# MIMXRT1064 register map
Vendor: nxp.com; File version: 1.0
CPU: CM7 r0p1, little endian, MPU, FPU, VTOR, 4 interrupt priority bits
Registers are 32-bit, read-write, reset 0x0 unless marked. A register's access mark holds for its fields unless they carry their own. Offsets are from the block's base; [hi:lo] are bit positions; {n}, {i} and the like mark numbered series; 'fields as' and 'values as' point back to an identical list.

## GPIO1 — GPIO
Base 0x401B8000
Same registers: GPIO5 0x400C0000, GPIO2 0x401BC000, GPIO3 0x401C0000, GPIO4 0x401C4000, GPIO10 0x401C8000, GPIO6 0x42000000, GPIO7 0x42004000, GPIO8 0x42008000, GPIO9 0x4200C000
0x00 DR — GPIO data register
  [31:0] DR — DR data bits
0x04 GDIR — GPIO direction register
  [31:0] GDIR — GPIO direction bits
0x08 PSR ro — GPIO pad status register
  [31:0] PSR — GPIO pad status bits
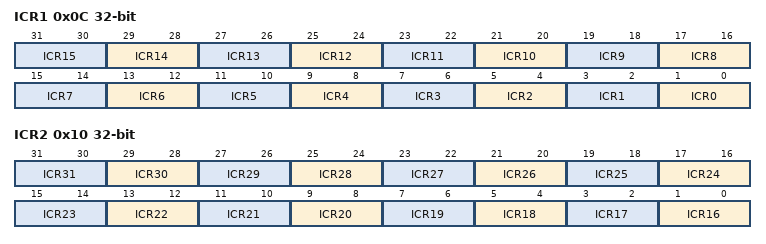
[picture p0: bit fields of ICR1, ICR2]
0x0C ICR1 — GPIO interrupt configuration register1
  [2n+1:2n] ICR{n} (n=0..15) — Interrupt configuration field for GPIO interrupt {n}
    0=LOW_LEVEL (Interrupt {n} is low-level sensitive.); 1=HIGH_LEVEL (Interrupt {n} is high-level sensitive.); 2=RISING_EDGE (Interrupt {n} is rising-edge sensitive.); 3=FALLING_EDGE (Interrupt {n} is falling-edge sensitive.)
0x10 ICR2 — GPIO interrupt configuration register2
  [2n-31:2n-32] ICR{n} (n=16..31) — Interrupt configuration field for GPIO interrupt {n}
    values as ICR1.ICR0
0x14 IMR — GPIO interrupt mask register
  [31:0] IMR — Interrupt Mask bits
0x18 ISR write-1-clears — GPIO interrupt status register
  [31:0] ISR write-1-clears — Interrupt status bits
0x1C EDGE_SEL — GPIO edge select register
  [31:0] GPIO_EDGE_SEL — Edge select
0x84 DR_SET wo — GPIO data register SET
  [31:0] DR_SET — Set
0x88 DR_CLEAR wo — GPIO data register CLEAR
  [31:0] DR_CLEAR — Clear
0x8C DR_TOGGLE wo — GPIO data register TOGGLE
  [31:0] DR_TOGGLE — Toggle

## KPP — KPP Registers
Base 0x401FC000; register names take the prefix KPP_
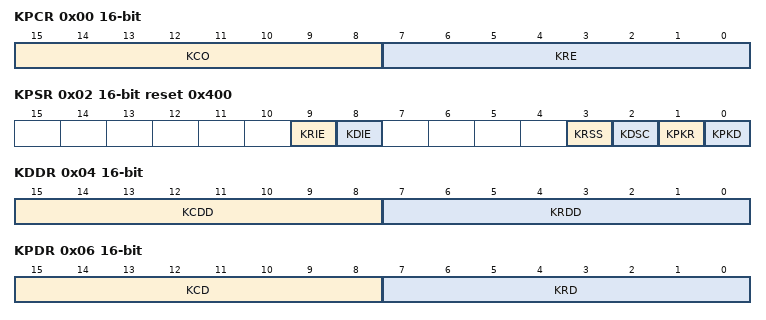
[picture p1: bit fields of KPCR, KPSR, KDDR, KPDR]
0x00 KPCR 16-bit — Keypad Control Register
  [15:8] KCO — Keypad Column Strobe Open-Drain Enable
    0=TOTEM_POLE (Column strobe output is totem pole drive.); 1=OPEN_DRAIN (Column strobe output is open drain.)
  [7:0] KRE — Keypad Row Enable
    0=Row is not included in the keypad key press detect; 1=Row is included in the keypad key press detect
0x02 KPSR 16-bit reset 0x400 — Keypad Status Register
  [9] KRIE — Keypad Release Interrupt Enable
    0=No interrupt request is generated when KPKR is set; 1=An interrupt request is generated when KPKR is set
  [8] KDIE — Keypad Key Depress Interrupt Enable
    0=No interrupt request is generated when KPKD is set; 1=An interrupt request is generated when KPKD is set
  [3] KRSS — Key Release Synchronizer Set
    0=No effect; 1=Set bits which sets keypad release synchronizer chain
  [2] KDSC — Key Depress Synchronizer Clear
    0=No effect; 1=Set bits that clear the keypad depress synchronizer chain
  [1] KPKR write-1-clears — Keypad Key Release
    0=No key release detected; 1=All keys have been released
  [0] KPKD write-1-clears — Keypad Key Depress
    0=No key presses detected; 1=A key has been depressed
0x04 KDDR 16-bit — Keypad Data Direction Register
  [15:8] KCDD — Keypad Column Data Direction Register
    0=INPUT (COLn pin is configured as an input.); 1=OUTPUT (COLn pin is configured as an output.)
  [7:0] KRDD — Keypad Row Data Direction
    0=INPUT (ROWn pin configured as an input.); 1=OUTPUT (ROWn pin configured as an output.)
0x06 KPDR 16-bit — Keypad Data Register
  [15:8] KCD — Keypad Column Data
  [7:0] KRD — Keypad Row Data

## USBNC1 — USB
Base 0x402E0000; register names take the prefix USBNC_; alternate view of USB1
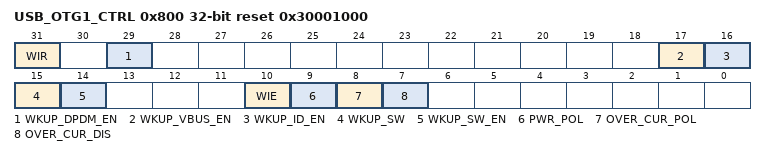
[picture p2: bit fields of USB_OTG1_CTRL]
0x800 USB_OTG1_CTRL reset 0x30001000 — USB OTG1 Control Register
  [31] WIR ro — OTG1 Wake-up Interrupt Request This bit indicates that a wake-up interrupt request is received on the OTG1 port
    0=No wake-up interrupt request received; 1=Wake-up Interrupt Request received
  [29] WKUP_DPDM_EN — Wake-up on DPDM change enable
    0=DPDM changes wake-up to be disabled only when VBUS is 0; 1=(Default) DPDM changes wake-up to be enabled, it is for device only
  [17] WKUP_VBUS_EN — OTG1 wake-up on VBUS change enable
    0=Disable; 1=Enable
  [16] WKUP_ID_EN — OTG1 Wake-up on ID change enable
    0=Disable; 1=Enable
  [15] WKUP_SW — OTG1 Software Wake-up
    0=Inactive; 1=Force wake-up
  [14] WKUP_SW_EN — OTG1 Software Wake-up Enable
    0=Disable; 1=Enable
  [10] WIE — OTG1 Wake-up Interrupt Enable This bit enables or disables the OTG1 wake-up interrupt
    0=Interrupt Disabled; 1=Interrupt Enabled
  [9] PWR_POL — OTG1 Power Polarity This bit should be set according to PMIC Power Pin polarity.
    0=PMIC Power Pin is Low active; 1=PMIC Power Pin is High active
  [8] OVER_CUR_POL — OTG1 Polarity of Overcurrent The polarity of OTG1 port overcurrent event
    0=High active (high on this signal represents an overcurrent condition); 1=Low active (low on this signal represents an overcurrent condition)
  [7] OVER_CUR_DIS — Disable OTG1 Overcurrent Detection
    0=Enables overcurrent detection; 1=Disables overcurrent detection
0x818 USB_OTG1_PHY_CTRL_0 — OTG1 UTMI PHY Control 0 Register
  [31] UTMI_CLK_VLD — Indicating whether OTG1 UTMI PHY clock is valid
    0=Invalid; 1=Valid
